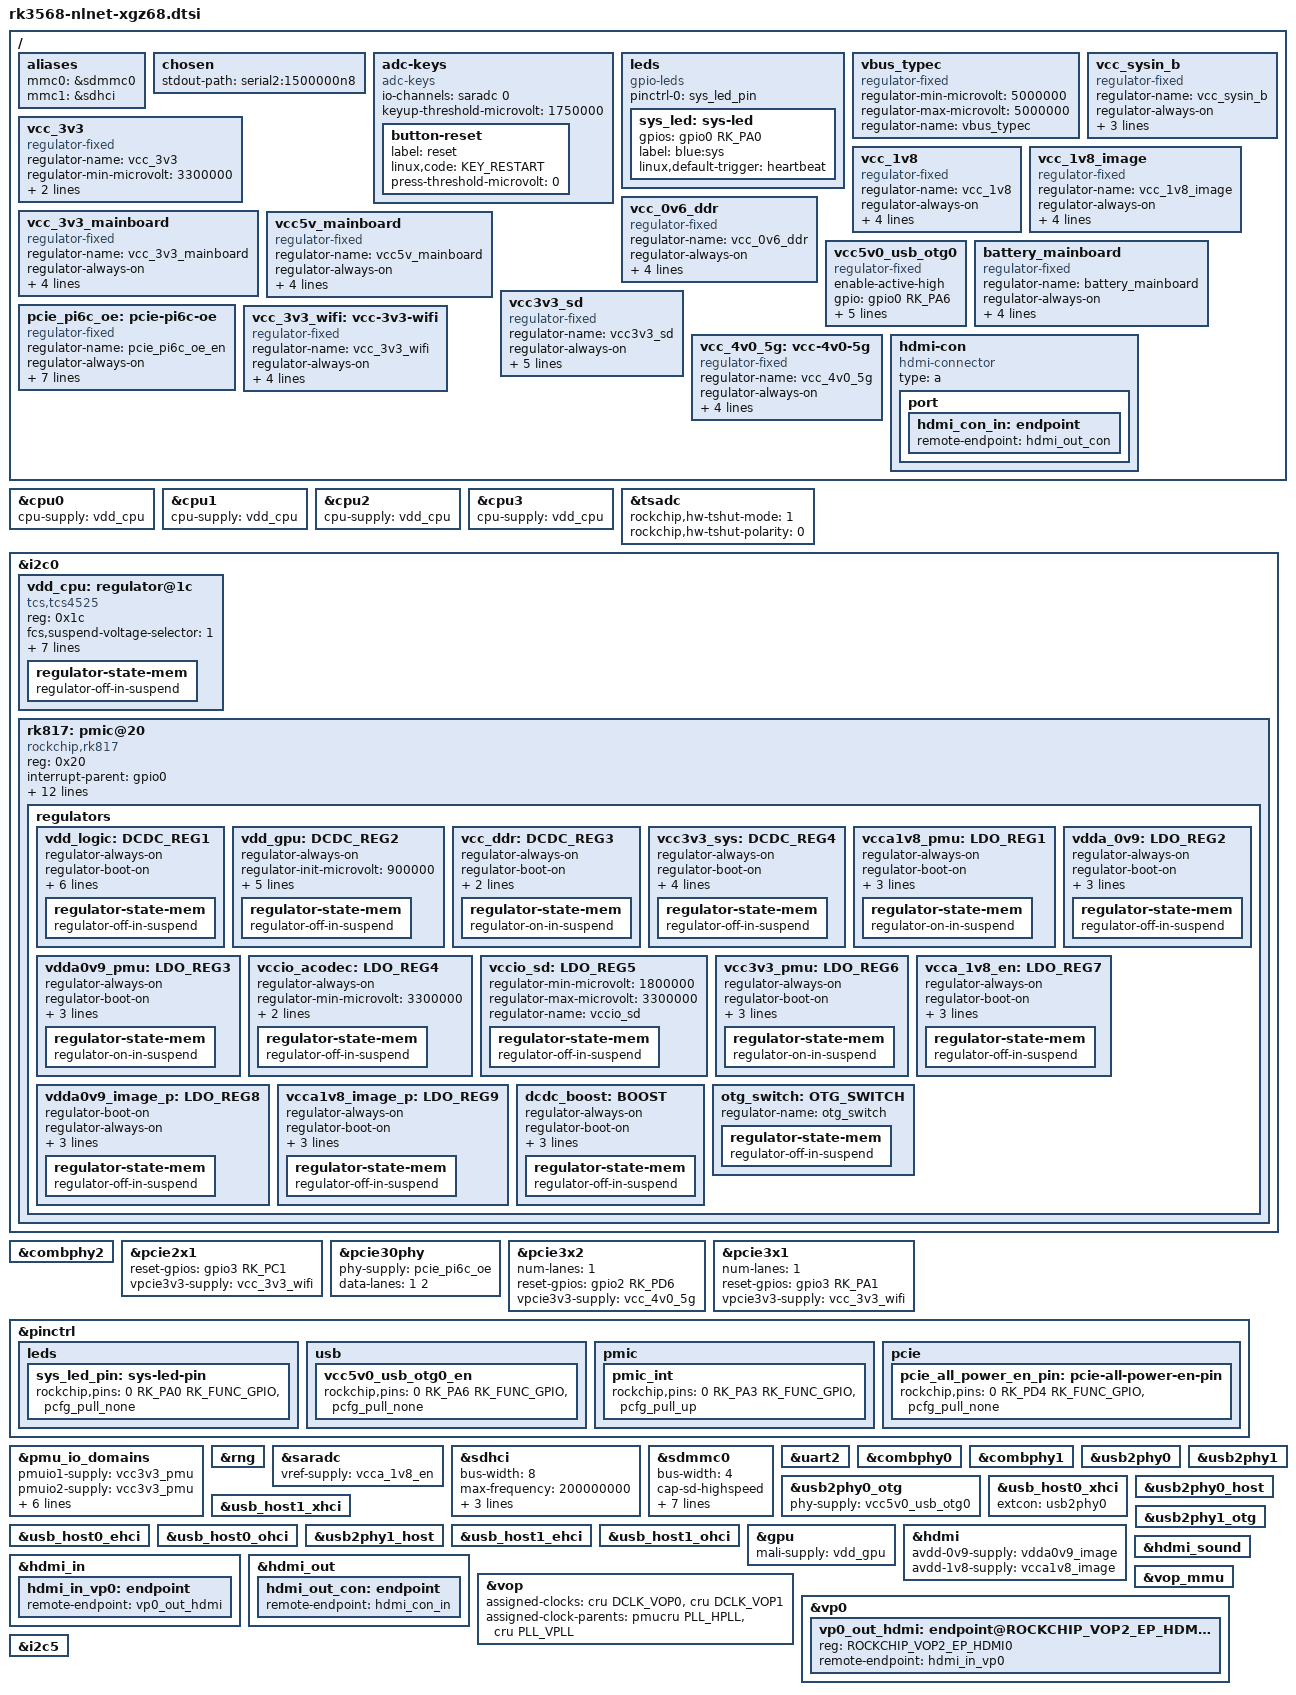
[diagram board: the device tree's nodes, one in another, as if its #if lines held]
// SPDX-License-Identifier: (GPL-2.0+ OR MIT)

#include <dt-bindings/gpio/gpio.h>
#include <dt-bindings/input/input.h>
#include <dt-bindings/pinctrl/rockchip.h>
#include <dt-bindings/soc/rockchip,vop2.h>
#include "rk3568.dtsi"

/ {
	aliases {
		mmc0 = &sdmmc0;
		mmc1 = &sdhci;
	};

	chosen {
		stdout-path = "serial2:1500000n8";
	};

	adc-keys {
		compatible = "adc-keys";
		io-channels = <&saradc 0>;
		io-channel-names = "buttons";
		keyup-threshold-microvolt = <1750000>;

		button-reset {
			label = "reset";
			linux,code = <KEY_RESTART>;
			press-threshold-microvolt = <0>;
		};
	};

	leds {
		compatible = "gpio-leds";
		pinctrl-0 = <&sys_led_pin>;
		pinctrl-names = "default";

		sys_led: sys-led {
			gpios = <&gpio0 RK_PA0 GPIO_ACTIVE_HIGH>;
			label = "blue:sys";
			linux,default-trigger = "heartbeat";
		};
	};

	vbus_typec: vbus_typec {
		compatible = "regulator-fixed";
		regulator-min-microvolt = <5000000>;
		regulator-max-microvolt = <5000000>;
		regulator-name = "vbus_typec";
	};

	vcc_sysin_b: vcc_sysin_b {
		compatible = "regulator-fixed";
		regulator-name = "vcc_sysin_b";
		regulator-always-on;
		regulator-boot-on;
		regulator-min-microvolt = <4000000>;
		regulator-max-microvolt = <4000000>;
	};

	vcc_3v3: vcc_3v3 {
		compatible = "regulator-fixed";
		regulator-name = "vcc_3v3";
		regulator-min-microvolt = <3300000>;
		regulator-max-microvolt = <3300000>;
		vin-supply = <&vcc3v3_sys>;
	};

	vcc_1v8: vcc_1v8 {
		compatible = "regulator-fixed";
		regulator-name = "vcc_1v8";
		regulator-always-on;
		regulator-boot-on;
		regulator-min-microvolt = <1800000>;
		regulator-max-microvolt = <1800000>;
		vin-supply = <&vcc_sysin_b>;
	};

	vcc_1v8_image: vcc_1v8_image {
		compatible = "regulator-fixed";
		regulator-name = "vcc_1v8_image";
		regulator-always-on;
		regulator-boot-on;
		regulator-min-microvolt = <1800000>;
		regulator-max-microvolt = <1800000>;
		vin-supply = <&vcc_1v8>;
	};

	vcc_0v6_ddr: vcc_0v6_ddr {
		compatible = "regulator-fixed";
		regulator-name = "vcc_0v6_ddr";
		regulator-always-on;
		regulator-boot-on;
		regulator-min-microvolt = <600000>;
		regulator-max-microvolt = <600000>;
		vin-supply = <&vcc_sysin_b>;
	};

	vcc_3v3_mainboard: vcc_3v3_mainboard {
		compatible = "regulator-fixed";
		regulator-name = "vcc_3v3_mainboard";
		regulator-always-on;
		regulator-boot-on;
		regulator-min-microvolt = <3300000>;
		regulator-max-microvolt = <3300000>;
		vin-supply = <&vbus_typec>;
	};

	vcc5v_mainboard: vcc5v_mainboard {
		compatible = "regulator-fixed";
		regulator-name = "vcc5v_mainboard";
		regulator-always-on;
		regulator-boot-on;
		regulator-min-microvolt = <5000000>;
		regulator-max-microvolt = <5000000>;
		vin-supply = <&vbus_typec>;
	};

	vcc5v0_usb_otg0: vcc5v0_usb_otg0 {
		compatible = "regulator-fixed";
		enable-active-high;
		gpio = <&gpio0 RK_PA6 GPIO_ACTIVE_HIGH>;
		pinctrl-names = "default";
		pinctrl-0 = <&vcc5v0_usb_otg0_en>;
		regulator-min-microvolt = <5000000>;
		regulator-max-microvolt = <5000000>;
		regulator-name = "vcc5v0_usb_otg0";
		vin-supply = <&vcc5v_mainboard>;
	};

	battery_mainboard: battery_mainboard {
		compatible = "regulator-fixed";
		regulator-name = "battery_mainboard";
		regulator-always-on;
		regulator-boot-on;
		regulator-min-microvolt = <4000000>;
		regulator-max-microvolt = <4000000>;
		vin-supply = <&vbus_typec>;
	};

	vcc3v3_sd: vcc3v3_sd {
		compatible = "regulator-fixed";
		regulator-name = "vcc3v3_sd";
		regulator-always-on;
		gpio = <&gpio0 RK_PA5 GPIO_ACTIVE_LOW>;
		pinctrl-names = "default";
		pinctrl-0 = <&sdmmc0_pwren>;
		regulator-min-microvolt = <3300000>;
		regulator-max-microvolt = <3300000>;
		vin-supply = <&vcc_3v3_mainboard>;
	};

	pcie_pi6c_oe: pcie-pi6c-oe {
		compatible = "regulator-fixed";
		regulator-name = "pcie_pi6c_oe_en";
		regulator-always-on;
		regulator-boot-on;
		enable-active-high;
		gpio = <&gpio0 RK_PD4 GPIO_ACTIVE_HIGH>;
		pinctrl-names = "default";
		pinctrl-0 = <&pcie_all_power_en_pin>;
		regulator-min-microvolt = <3300000>;
		regulator-max-microvolt = <3300000>;
		vin-supply = <&vcc5v_mainboard>;
	};

	vcc_3v3_wifi: vcc-3v3-wifi {
		compatible = "regulator-fixed";
		regulator-name = "vcc_3v3_wifi";
		regulator-always-on;
		enable-active-high;
		regulator-min-microvolt = <3300000>;
		regulator-max-microvolt = <3300000>;
		vin-supply = <&vcc_3v3_mainboard>;
	};

	vcc_4v0_5g: vcc-4v0-5g {
		compatible = "regulator-fixed";
		regulator-name = "vcc_4v0_5g";
		regulator-always-on;
		enable-active-high;
		regulator-min-microvolt = <4000000>;
		regulator-max-microvolt = <4000000>;
		vin-supply = <&battery_mainboard>;
	};

#ifdef DTS_NO_LEGACY
	hdmi-con {
		compatible = "hdmi-connector";
		type = "a";

		port {
			hdmi_con_in: endpoint {
				remote-endpoint = <&hdmi_out_con>;
			};
		};
	};
#endif
};

&cpu0 {
	cpu-supply = <&vdd_cpu>;
};

&cpu1 {
	cpu-supply = <&vdd_cpu>;
};

&cpu2 {
	cpu-supply = <&vdd_cpu>;
};

&cpu3 {
	cpu-supply = <&vdd_cpu>;
};

&tsadc {
	rockchip,hw-tshut-mode = <1>;
	rockchip,hw-tshut-polarity = <0>;
	status = "okay";
};

&i2c0 {
	status = "okay";

	vdd_cpu: regulator@1c {
		compatible = "tcs,tcs4525";
		reg = <0x1c>;
		fcs,suspend-voltage-selector = <1>;
		regulator-name = "vdd_cpu";
		regulator-always-on;
		regulator-boot-on;
		regulator-min-microvolt = <800000>;
		regulator-max-microvolt = <1150000>;
		regulator-ramp-delay = <2300>;
		vin-supply = <&vcc_sysin_b>;

		regulator-state-mem {
			regulator-off-in-suspend;
		};
	};

	rk817: pmic@20 {
		compatible = "rockchip,rk817";
		reg = <0x20>;
		interrupt-parent = <&gpio0>;
		interrupts = <RK_PA3 IRQ_TYPE_LEVEL_LOW>;
		pinctrl-names = "default";
		pinctrl-0 = <&pmic_int>;
		wakeup-source;
		#clock-cells = <1>;

		vcc1-supply = <&vcc_sysin_b>;
		vcc2-supply = <&vcc_sysin_b>;
		vcc3-supply = <&vcc_sysin_b>;
		vcc4-supply = <&vcc_sysin_b>;
		vcc5-supply = <&vcc_sysin_b>;
		vcc6-supply = <&vcc_sysin_b>;
		vcc7-supply = <&vcc_sysin_b>;
		vcc8-supply = <&vcc_sysin_b>;
		vcc9-supply = <&dcdc_boost>;

		regulators {
			vdd_logic: DCDC_REG1 {
				regulator-always-on;
				regulator-boot-on;
				regulator-init-microvolt = <900000>;
				regulator-initial-mode = <0x2>;
				regulator-min-microvolt = <500000>;
				regulator-max-microvolt = <1350000>;
				regulator-name = "vdd_logic";
				regulator-ramp-delay = <6001>;

				regulator-state-mem {
					regulator-off-in-suspend;
				};
			};

			vdd_gpu: DCDC_REG2 {
				regulator-always-on;
				regulator-init-microvolt = <900000>;
				regulator-initial-mode = <0x2>;
				regulator-min-microvolt = <500000>;
				regulator-max-microvolt = <1350000>;
				regulator-name = "vdd_gpu";
				regulator-ramp-delay = <6001>;

				regulator-state-mem {
					regulator-off-in-suspend;
				};
			};

			vcc_ddr: DCDC_REG3 {
				regulator-always-on;
				regulator-boot-on;
				regulator-initial-mode = <0x2>;
				regulator-name = "vcc_ddr";

				regulator-state-mem {
					regulator-on-in-suspend;
				};
			};

			vcc3v3_sys: DCDC_REG4 {
				regulator-always-on;
				regulator-boot-on;
				regulator-min-microvolt = <3300000>;
				regulator-max-microvolt = <3300000>;
				regulator-initial-mode = <0x2>;
				regulator-name = "vcc3v3_sys";

				regulator-state-mem {
					regulator-off-in-suspend;
				};
			};

			vcca1v8_pmu: LDO_REG1 {
				regulator-always-on;
				regulator-boot-on;
				regulator-min-microvolt = <1800000>;
				regulator-max-microvolt = <1800000>;
				regulator-name = "vcca1v8_pmu";

				regulator-state-mem {
					regulator-on-in-suspend;
				};
			};

			vdda_0v9: LDO_REG2 {
				regulator-always-on;
				regulator-boot-on;
				regulator-min-microvolt = <900000>;
				regulator-max-microvolt = <900000>;
				regulator-name = "vdda_0v9";

				regulator-state-mem {
					regulator-off-in-suspend;
				};
			};

			vdda0v9_pmu: LDO_REG3 {
				regulator-always-on;
				regulator-boot-on;
				regulator-min-microvolt = <900000>;
				regulator-max-microvolt = <900000>;
				regulator-name = "vdda0v9_pmu";

				regulator-state-mem {
					regulator-on-in-suspend;
				};
			};

			vccio_acodec: LDO_REG4 {
				regulator-always-on;
				regulator-min-microvolt = <3300000>;
				regulator-max-microvolt = <3300000>;
				regulator-name = "vccio_acodec";

				regulator-state-mem {
					regulator-off-in-suspend;
				};
			};

			vccio_sd: LDO_REG5 {
				regulator-min-microvolt = <1800000>;
				regulator-max-microvolt = <3300000>;
				regulator-name = "vccio_sd";

				regulator-state-mem {
					regulator-off-in-suspend;
				};
			};

			vcc3v3_pmu: LDO_REG6 {
				regulator-always-on;
				regulator-boot-on;
				regulator-min-microvolt = <3300000>;
				regulator-max-microvolt = <3300000>;
				regulator-name = "vcc3v3_pmu";

				regulator-state-mem {
					regulator-on-in-suspend;
				};
			};

			vcca_1v8_en: LDO_REG7 {
				regulator-always-on;
				regulator-boot-on;
				regulator-min-microvolt = <1800000>;
				regulator-max-microvolt = <1800000>;
				regulator-name = "vcca_1v8_en";

				regulator-state-mem {
					regulator-off-in-suspend;
				};
			};

			vdda0v9_image_p: LDO_REG8 {
				regulator-boot-on;
				regulator-always-on;
				regulator-min-microvolt = <900000>;
				regulator-max-microvolt = <900000>;
				regulator-name = "vdda0v9_image_p";

				regulator-state-mem {
					regulator-off-in-suspend;
				};
			};

			vcca1v8_image_p: LDO_REG9 {
				regulator-always-on;
				regulator-boot-on;
				regulator-min-microvolt = <1800000>;
				regulator-max-microvolt = <1800000>;
				regulator-name = "vcca1v8_image_p";

				regulator-state-mem {
					regulator-off-in-suspend;
				};
			};

			dcdc_boost: BOOST {
				regulator-always-on;
				regulator-boot-on;
				regulator-min-microvolt = <4700000>;
				regulator-max-microvolt = <5400000>;
				regulator-name = "boost";

				regulator-state-mem {
					regulator-off-in-suspend;
				};
			};

			otg_switch: OTG_SWITCH {
				regulator-name = "otg_switch";

				regulator-state-mem {
					regulator-off-in-suspend;
				};
			};
		};
	};
};

&combphy2 {
	status = "okay";
};

&pcie2x1 {
	reset-gpios = <&gpio3 RK_PC1 GPIO_ACTIVE_HIGH>;
	vpcie3v3-supply = <&vcc_3v3_wifi>;
	status = "okay";
};

&pcie30phy {
	phy-supply = <&pcie_pi6c_oe>;
	data-lanes = <1 2>;
	status = "okay";
};

&pcie3x2 {
	num-lanes = <1>;
	reset-gpios = <&gpio2 RK_PD6 GPIO_ACTIVE_HIGH>;
	vpcie3v3-supply = <&vcc_4v0_5g>;
	status = "okay";
};

&pcie3x1 {
	num-lanes = <1>;
	reset-gpios = <&gpio3 RK_PA1 GPIO_ACTIVE_HIGH>;
	vpcie3v3-supply = <&vcc_3v3_wifi>;
	status = "okay";
};

&pinctrl {
	leds {
		sys_led_pin: sys-led-pin {
			rockchip,pins = <0 RK_PA0 RK_FUNC_GPIO &pcfg_pull_none>;
		};
	};

	usb {
		vcc5v0_usb_otg0_en: vcc5v0_usb_otg0_en {
			rockchip,pins = <0 RK_PA6 RK_FUNC_GPIO &pcfg_pull_none>;
		};
	};

	pmic {
		pmic_int: pmic_int {
			rockchip,pins = <0 RK_PA3 RK_FUNC_GPIO &pcfg_pull_up>;
		};
	};

	pcie {
		pcie_all_power_en_pin: pcie-all-power-en-pin {
			rockchip,pins = <0 RK_PD4 RK_FUNC_GPIO &pcfg_pull_none>;
		};
	};
};

&pmu_io_domains {
	pmuio1-supply = <&vcc3v3_pmu>;
	pmuio2-supply = <&vcc3v3_pmu>;
	vccio1-supply = <&vccio_acodec>;
	vccio3-supply = <&vccio_sd>;
	vccio4-supply = <&vcca1v8_pmu>;
	vccio5-supply = <&vcc_1v8>;
	vccio6-supply = <&vcca1v8_image_p>;
	vccio7-supply = <&vcc_3v3>;
	status = "okay";
};

&rng {
	status = "okay";
};

&saradc {
	vref-supply = <&vcca_1v8_en>;
	status = "okay";
};

&sdhci {
	bus-width = <8>;
	max-frequency = <200000000>;
	non-removable;
	pinctrl-names = "default";
	pinctrl-0 = <&emmc_bus8 &emmc_clk &emmc_cmd &emmc_datastrobe>;
	status = "okay";
};

&sdmmc0 {
	bus-width = <4>;
	cap-sd-highspeed;
	cd-gpios = <&gpio0 RK_PA4 GPIO_ACTIVE_LOW>;
	disable-wp;
	pinctrl-names = "default";
	pinctrl-0 = <&sdmmc0_bus4 &sdmmc0_clk &sdmmc0_cmd &sdmmc0_det>;
	sd-uhs-sdr104;
	vmmc-supply = <&vcc3v3_sd>;
	vqmmc-supply = <&vccio_sd>;
	status = "okay";
};

&uart2 {
	status = "okay";
};

&combphy0 {
	status = "okay";
};

&combphy1 {
	status = "okay";
};

&usb2phy0 {
	status = "okay";
};

&usb2phy1 {
	status = "okay";
};

&usb2phy0_otg {
	phy-supply = <&vcc5v0_usb_otg0>;
	status = "okay";
};

&usb_host0_xhci {
	extcon = <&usb2phy0>;
	status = "okay";
};

&usb2phy0_host {
	status = "okay";
};

&usb_host1_xhci {
	status = "okay";
};

&usb2phy1_otg {
	status = "okay";
};

&usb_host0_ehci {
	status = "okay";
};

&usb_host0_ohci {
	status = "okay";
};

&usb2phy1_host {
	status = "okay";
};

&usb_host1_ehci {
	status = "okay";
};

&usb_host1_ohci {
	status = "okay";
};

#ifdef DTS_NO_LEGACY
&gpu {
	mali-supply = <&vdd_gpu>;
	status = "okay";
};

&hdmi {
	avdd-0v9-supply = <&vdda0v9_image>;
	avdd-1v8-supply = <&vcca1v8_image>;
	status = "okay";
};

&hdmi_in {
	hdmi_in_vp0: endpoint {
		remote-endpoint = <&vp0_out_hdmi>;
	};
};

&hdmi_out {
	hdmi_out_con: endpoint {
		remote-endpoint = <&hdmi_con_in>;
	};
};

&hdmi_sound {
	status = "okay";
};
#endif

#ifdef DTS_NO_LEGACY
&vop {
	assigned-clocks = <&cru DCLK_VOP0>, <&cru DCLK_VOP1>;
	assigned-clock-parents = <&pmucru PLL_HPLL>, <&cru PLL_VPLL>;
	status = "okay";
};

&vop_mmu {
	status = "okay";
};

&vp0 {
	vp0_out_hdmi: endpoint@ROCKCHIP_VOP2_EP_HDMI0 {
		reg = <ROCKCHIP_VOP2_EP_HDMI0>;
		remote-endpoint = <&hdmi_in_vp0>;
	};
};
#endif

&i2c5 {
	status = "okay";
};
